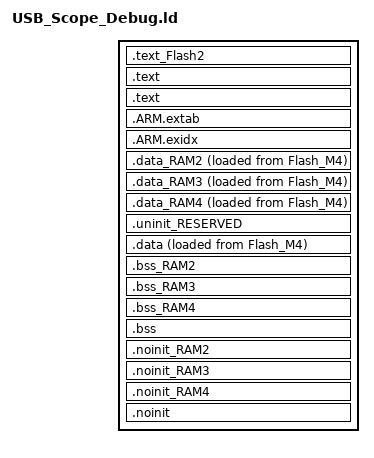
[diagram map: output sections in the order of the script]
/*
 * GENERATED FILE - DO NOT EDIT
 * (c) Code Red Technologies Ltd, 2008-13
 * (c) NXP Semiconductors 2013-2015
 * Generated linker script file for LPC4370
 * Created from generic_c.ld (LPCXpresso v7.6 (2 [Build 326] [2015-02-02] ))
 * By LPCXpresso v7.6.2 [Build 326] [2015-02-02]  on Tue May 05 23:29:29 JST 2015
 */


INCLUDE "USB_Scope_Debug_lib.ld"
INCLUDE "USB_Scope_Debug_mem.ld"

ENTRY(ResetISR)

SECTIONS
{
    
    .text_Flash2 : ALIGN(4)
    {
       FILL(0xff)
       __core_m0app_START__ = .; /* start of slave image */
         KEEP(*(.core_m0app))
         KEEP(*(.core_m0app.data_*)) KEEP(*(.core_m0app.data))
       __core_m0app_END__ = .; /* end of slave image */
       ASSERT(!(__core_m0app_START__ == __core_m0app_END__), "No slave code for _core_m0app");
       ASSERT( (ABSOLUTE(__core_m0app_START__) == __vectors_start___core_m0app), "M0APP execute address differs from address provided in source image");
    	*(.text_Flash2*) /* for compatibility with previous releases */
    	*(.text_Flash_M0*) /* for compatibility with previous releases */
    	*(.text.$Flash2*)
    	*(.text.$Flash_M0*)
    	*(.rodata.$Flash2*)
    	*(.rodata.$Flash_M0*)
    } > Flash_M0

    /* MAIN TEXT SECTION */    
    .text : ALIGN(4)
    {
        FILL(0xff)
        __vectors_start__ = ABSOLUTE(.) ;
        KEEP(*(.isr_vector))
        
        /* Global Section Table */
        . = ALIGN(4) ;
        __section_table_start = .;
        __data_section_table = .;
        LONG(LOADADDR(.data));
        LONG(    ADDR(.data));
        LONG(  SIZEOF(.data));
        LONG(LOADADDR(.data_RAM2));
        LONG(    ADDR(.data_RAM2));
        LONG(  SIZEOF(.data_RAM2));
        LONG(LOADADDR(.data_RAM3));
        LONG(    ADDR(.data_RAM3));
        LONG(  SIZEOF(.data_RAM3));
        LONG(LOADADDR(.data_RAM4));
        LONG(    ADDR(.data_RAM4));
        LONG(  SIZEOF(.data_RAM4));
        __data_section_table_end = .;
        __bss_section_table = .;
        LONG(    ADDR(.bss));
        LONG(  SIZEOF(.bss));
        LONG(    ADDR(.bss_RAM2));
        LONG(  SIZEOF(.bss_RAM2));
        LONG(    ADDR(.bss_RAM3));
        LONG(  SIZEOF(.bss_RAM3));
        LONG(    ADDR(.bss_RAM4));
        LONG(  SIZEOF(.bss_RAM4));
        __bss_section_table_end = .;
        __section_table_end = . ;
        /* End of Global Section Table */
        

        *(.after_vectors*)
        
        /* Code Read Protect data */
        . = 0x000002FC ;
        PROVIDE(__CRP_WORD_START__ = .) ;
        KEEP(*(.crp))
        PROVIDE(__CRP_WORD_END__ = .) ;
        ASSERT(!(__CRP_WORD_START__ == __CRP_WORD_END__), "Linker CRP Enabled, but no CRP_WORD provided within application");
        /* End of Code Read Protect */
        
    } >Flash_M4
    
    .text : ALIGN(4)    
    {
         *(.text*)
        *(.rodata .rodata.* .constdata .constdata.*)
        . = ALIGN(4);
        
    } > Flash_M4

    /*
     * for exception handling/unwind - some Newlib functions (in common
     * with C++ and STDC++) use this. 
     */
    .ARM.extab : ALIGN(4)
    {
    	*(.ARM.extab* .gnu.linkonce.armextab.*)
    } > Flash_M4
    __exidx_start = .;
    
    .ARM.exidx : ALIGN(4)
    {
    	*(.ARM.exidx* .gnu.linkonce.armexidx.*)
    } > Flash_M4
    __exidx_end = .;
    
    _etext = .;
        
    
    /* DATA section for RamLoc72 */
    .data_RAM2 : ALIGN(4)
    {
       FILL(0xff)
       PROVIDE(__start_data_RAM2 = .) ;
       *(.ramfunc.$RAM2)
       *(.ramfunc.$RamLoc72)
    	*(.data.$RAM2*)
    	*(.data.$RamLoc72*)
       . = ALIGN(4) ;
       PROVIDE(__end_data_RAM2 = .) ;
    } > RamLoc72 AT>Flash_M4
    
    /* DATA section for RamM0Sub16 */
    .data_RAM3 : ALIGN(4)
    {
       FILL(0xff)
       PROVIDE(__start_data_RAM3 = .) ;
       *(.ramfunc.$RAM3)
       *(.ramfunc.$RamM0Sub16)
    	*(.data.$RAM3*)
    	*(.data.$RamM0Sub16*)
       . = ALIGN(4) ;
       PROVIDE(__end_data_RAM3 = .) ;
    } > RamM0Sub16 AT>Flash_M4
    
    /* DATA section for RamM0Sub2 */
    .data_RAM4 : ALIGN(4)
    {
       FILL(0xff)
       PROVIDE(__start_data_RAM4 = .) ;
       *(.ramfunc.$RAM4)
       *(.ramfunc.$RamM0Sub2)
    	*(.data.$RAM4*)
    	*(.data.$RamM0Sub2*)
       . = ALIGN(4) ;
       PROVIDE(__end_data_RAM4 = .) ;
    } > RamM0Sub2 AT>Flash_M4
    
    /* MAIN DATA SECTION */
    

    .uninit_RESERVED : ALIGN(4)
    {
        KEEP(*(.bss.$RESERVED*))
        . = ALIGN(4) ;
        _end_uninit_RESERVED = .;
    } > RamLoc128

	
	/* Main DATA section (RamLoc128) */
	.data : ALIGN(4)
	{
	   FILL(0xff)
	   _data = . ;
	   *(vtable)
	   *(.ramfunc*)
	   *(.data*)
	   . = ALIGN(4) ;
	   _edata = . ;
	} > RamLoc128 AT>Flash_M4

    /* BSS section for RamLoc72 */
    .bss_RAM2 : ALIGN(4)
    {
       PROVIDE(__start_bss_RAM2 = .) ;
    	*(.bss.$RAM2*)
    	*(.bss.$RamLoc72*)
       . = ALIGN(4) ;
       PROVIDE(__end_bss_RAM2 = .) ;
    } > RamLoc72
    /* BSS section for RamM0Sub16 */
    .bss_RAM3 : ALIGN(4)
    {
       PROVIDE(__start_bss_RAM3 = .) ;
    	*(.bss.$RAM3*)
    	*(.bss.$RamM0Sub16*)
       . = ALIGN(4) ;
       PROVIDE(__end_bss_RAM3 = .) ;
    } > RamM0Sub16
    /* BSS section for RamM0Sub2 */
    .bss_RAM4 : ALIGN(4)
    {
       PROVIDE(__start_bss_RAM4 = .) ;
    	*(.bss.$RAM4*)
    	*(.bss.$RamM0Sub2*)
       . = ALIGN(4) ;
       PROVIDE(__end_bss_RAM4 = .) ;
    } > RamM0Sub2

    /* MAIN BSS SECTION */
    .bss : ALIGN(4)
    {
        _bss = .;
        *(.bss*)
        *(COMMON)
        . = ALIGN(4) ;
        _ebss = .;
        PROVIDE(end = .);
    } > RamLoc128
        
    /* NOINIT section for RamLoc72 */
    .noinit_RAM2 (NOLOAD) : ALIGN(4)
    {
    	*(.noinit.$RAM2*)
    	*(.noinit.$RamLoc72*)
       . = ALIGN(4) ;
    } > RamLoc72 
    /* NOINIT section for RamM0Sub16 */
    .noinit_RAM3 (NOLOAD) : ALIGN(4)
    {
    	*(.noinit.$RAM3*)
    	*(.noinit.$RamM0Sub16*)
       . = ALIGN(4) ;
    } > RamM0Sub16 
    /* NOINIT section for RamM0Sub2 */
    .noinit_RAM4 (NOLOAD) : ALIGN(4)
    {
    	*(.noinit.$RAM4*)
    	*(.noinit.$RamM0Sub2*)
       . = ALIGN(4) ;
    } > RamM0Sub2 
    
    /* DEFAULT NOINIT SECTION */
    .noinit (NOLOAD): ALIGN(4)
    {
        _noinit = .;
        *(.noinit*) 
         . = ALIGN(4) ;
        _end_noinit = .;
    } > RamLoc128
    
    PROVIDE(_pvHeapStart = DEFINED(__user_heap_base) ? __user_heap_base : .);
    PROVIDE(_vStackTop = DEFINED(__user_stack_top) ? __user_stack_top : __top_RamLoc128 - 0);
}
